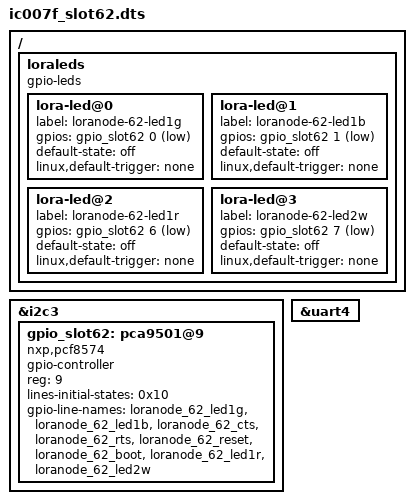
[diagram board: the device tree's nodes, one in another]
/dts-v1/;


/plugin/;

/ {
	fragment@0 {
		target = <&i2c3>;
		__overlay__ {
			#address-cells = <1>;
			#size-cells = <0>;
			gpio_slot62: pca9501@9 {
				compatible = "nxp,pcf8574";
				gpio-controller;
				#gpio-cells = <2>;
				reg = <9>;
				lines-initial-states = <0x10>;
                gpio-line-names ="loranode_62_led1g",
                "loranode_62_led1b",
                "loranode_62_cts",
                "loranode_62_rts",
                "loranode_62_reset",
                "loranode_62_boot",
                "loranode_62_led1r",
                "loranode_62_led2w";
                
			};
		};
	};

	fragment@3 {
		
		target = <&uart4>;
		__overlay__ {
			status = "okay";
		};

	};

	fragment@4 {
		target-path = "/";
		__overlay__ {
			loraleds {
				compatible = "gpio-leds";
				lora-led@0 {
					label = "loranode-62-led1g";
					gpios = <&gpio_slot62 0 1>;
					default-state = "off";
					linux,default-trigger = "none";
				};
				lora-led@1 {
					label = "loranode-62-led1b";
					gpios = <&gpio_slot62 1 1>;
					default-state = "off";
					linux,default-trigger = "none";
				};				
				lora-led@2 {
					label = "loranode-62-led1r";
					gpios = <&gpio_slot62 6 1>;
					default-state = "off";
					linux,default-trigger = "none";
				};
				lora-led@3 {
					label = "loranode-62-led2w";
					gpios = <&gpio_slot62 7 1>;
					default-state = "off";
					linux,default-trigger = "none";
				};
			};
		};
	};
};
